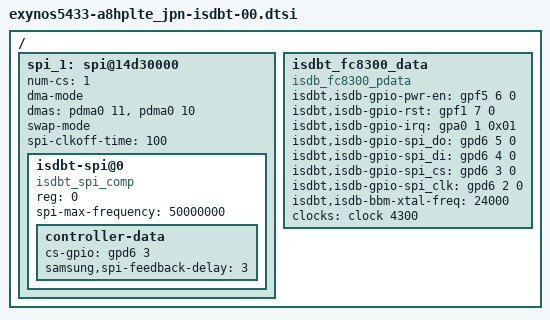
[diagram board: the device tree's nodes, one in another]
 /* Copyright (c) 2012-2014, The Linux Foundation. All rights reserved.
 *
 * This program is free software; you can redistribute it and/or modify
 * it under the terms of the GNU General Public License version 2 and
 * only version 2 as published by the Free Software Foundation.
 *
 * This program is distributed in the hope that it will be useful,
 * but WITHOUT ANY WARRANTY; without even the implied warranty of
 * MERCHANTABILITY or FITNESS FOR A PARTICULAR PURPOSE.  See the
 * GNU General Public License for more details.
 */

/{
	spi_1: spi@14d30000 {
		#address-cells = <1>;
		#size-cells = <0>;
		num-cs = <1>;

		dma-mode;
		dmas = <&pdma0 11
			&pdma0 10>;
		dma-names = "tx", "rx";

		swap-mode;
		status = "ok";
		spi-clkoff-time = <100>;

		isdbt-spi@0 {
			compatible = "isdbt_spi_comp";
			reg = <0>;
			spi-max-frequency = <50000000>;
			controller-data {
				cs-gpio = <&gpd6 3 0>;
				samsung,spi-feedback-delay = <3>;
			};
		};
	};

	isdbt_fc8300_data {
		compatible = "isdb_fc8300_pdata";
		isdbt,isdb-gpio-pwr-en = <&gpf5 6 0>;
		isdbt,isdb-gpio-rst = <&gpf1 7 0>;
		isdbt,isdb-gpio-irq = <&gpa0 1 0x01>;
		/* isdbt,isdb-gpio-i2c_sda = <&gpd0 2 0>; */
		/* isdbt,isdb-gpio-i2c_scl = <&gpd0 3 0>; */
		isdbt,isdb-gpio-spi_do = <&gpd6 5 0>;
		isdbt,isdb-gpio-spi_di = <&gpd6 4 0>;
		isdbt,isdb-gpio-spi_cs = <&gpd6 3 0>;
		isdbt,isdb-gpio-spi_clk = <&gpd6 2 0>;
		isdbt,isdb-bbm-xtal-freq = <24000>;
		/* isdbt,ldo_vdd_1p8 = "VDD_1.8V_ESE"; */

		clocks = <&clock 4300>;
		clock-names = "isdbt_clkout";
	};

};
